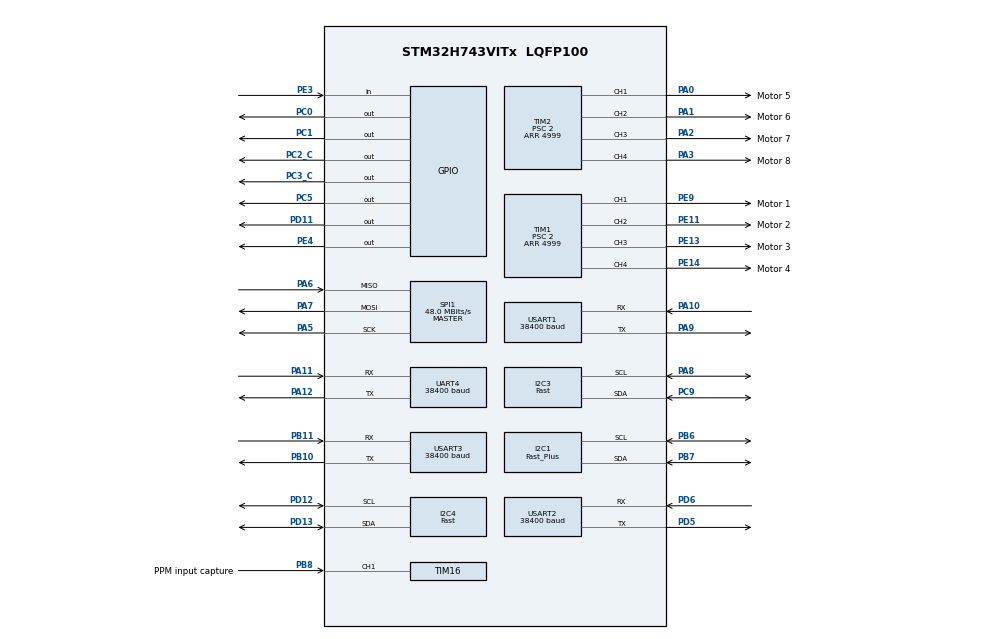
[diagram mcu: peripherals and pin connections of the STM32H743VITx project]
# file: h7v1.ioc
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Bdma.I2C4_RX.0.Direction=DMA_PERIPH_TO_MEMORY
Bdma.I2C4_RX.0.EventEnable=DISABLE
Bdma.I2C4_RX.0.Instance=BDMA_Channel0
Bdma.I2C4_RX.0.MemDataAlignment=DMA_MDATAALIGN_BYTE
Bdma.I2C4_RX.0.MemInc=DMA_MINC_ENABLE
Bdma.I2C4_RX.0.Mode=DMA_NORMAL
Bdma.I2C4_RX.0.PeriphDataAlignment=DMA_PDATAALIGN_BYTE
Bdma.I2C4_RX.0.PeriphInc=DMA_PINC_DISABLE
Bdma.I2C4_RX.0.Polarity=HAL_DMAMUX_REQ_GEN_RISING
Bdma.I2C4_RX.0.Priority=DMA_PRIORITY_LOW
Bdma.I2C4_RX.0.RequestNumber=1
Bdma.I2C4_RX.0.SignalID=NONE
Bdma.I2C4_RX.0.SyncEnable=DISABLE
Bdma.I2C4_RX.0.SyncPolarity=HAL_DMAMUX_SYNC_NO_EVENT
Bdma.I2C4_RX.0.SyncRequestNumber=1
Bdma.I2C4_RX.0.SyncSignalID=NONE
Bdma.I2C4_TX.1.Direction=DMA_MEMORY_TO_PERIPH
Bdma.I2C4_TX.1.EventEnable=DISABLE
Bdma.I2C4_TX.1.Instance=BDMA_Channel1
Bdma.I2C4_TX.1.MemDataAlignment=DMA_MDATAALIGN_BYTE
Bdma.I2C4_TX.1.MemInc=DMA_MINC_ENABLE
Bdma.I2C4_TX.1.Mode=DMA_NORMAL
Bdma.I2C4_TX.1.PeriphDataAlignment=DMA_PDATAALIGN_BYTE
Bdma.I2C4_TX.1.PeriphInc=DMA_PINC_DISABLE
Bdma.I2C4_TX.1.Polarity=HAL_DMAMUX_REQ_GEN_RISING
Bdma.I2C4_TX.1.Priority=DMA_PRIORITY_LOW
Bdma.I2C4_TX.1.RequestNumber=1
Bdma.I2C4_TX.1.SignalID=NONE
Bdma.I2C4_TX.1.SyncEnable=DISABLE
Bdma.I2C4_TX.1.SyncPolarity=HAL_DMAMUX_SYNC_NO_EVENT
Bdma.I2C4_TX.1.SyncRequestNumber=1
Bdma.I2C4_TX.1.SyncSignalID=NONE
Bdma.Request0=I2C4_RX
Bdma.Request1=I2C4_TX
Bdma.RequestsNb=2
CORTEX_M7.CPU_DCache=Disabled
CORTEX_M7.CPU_ICache=Disabled
CORTEX_M7.default_mode_Activation=0
Dma.I2C1_RX.0.Direction=DMA_PERIPH_TO_MEMORY
Dma.I2C1_RX.0.EventEnable=DISABLE
Dma.I2C1_RX.0.FIFOMode=DMA_FIFOMODE_DISABLE
Dma.I2C1_RX.0.Instance=DMA1_Stream0
Dma.I2C1_RX.0.MemDataAlignment=DMA_MDATAALIGN_BYTE
Dma.I2C1_RX.0.MemInc=DMA_MINC_ENABLE
Dma.I2C1_RX.0.Mode=DMA_NORMAL
Dma.I2C1_RX.0.PeriphDataAlignment=DMA_PDATAALIGN_BYTE
Dma.I2C1_RX.0.PeriphInc=DMA_PINC_DISABLE
Dma.I2C1_RX.0.Polarity=HAL_DMAMUX_REQ_GEN_RISING
Dma.I2C1_RX.0.Priority=DMA_PRIORITY_LOW
Dma.I2C1_RX.0.RequestNumber=1
Dma.I2C1_RX.0.SignalID=NONE
Dma.I2C1_RX.0.SyncEnable=DISABLE
Dma.I2C1_RX.0.SyncPolarity=HAL_DMAMUX_SYNC_NO_EVENT
Dma.I2C1_RX.0.SyncRequestNumber=1
Dma.I2C1_RX.0.SyncSignalID=NONE
Dma.I2C1_TX.1.Direction=DMA_MEMORY_TO_PERIPH
Dma.I2C1_TX.1.EventEnable=DISABLE
Dma.I2C1_TX.1.FIFOMode=DMA_FIFOMODE_DISABLE
Dma.I2C1_TX.1.Instance=DMA2_Stream0
Dma.I2C1_TX.1.MemDataAlignment=DMA_MDATAALIGN_BYTE
Dma.I2C1_TX.1.MemInc=DMA_MINC_ENABLE
Dma.I2C1_TX.1.Mode=DMA_NORMAL
Dma.I2C1_TX.1.PeriphDataAlignment=DMA_PDATAALIGN_BYTE
Dma.I2C1_TX.1.PeriphInc=DMA_PINC_DISABLE
Dma.I2C1_TX.1.Polarity=HAL_DMAMUX_REQ_GEN_RISING
Dma.I2C1_TX.1.Priority=DMA_PRIORITY_LOW
Dma.I2C1_TX.1.RequestNumber=1
Dma.I2C1_TX.1.SignalID=NONE
Dma.I2C1_TX.1.SyncEnable=DISABLE
Dma.I2C1_TX.1.SyncPolarity=HAL_DMAMUX_SYNC_NO_EVENT
Dma.I2C1_TX.1.SyncRequestNumber=1
Dma.I2C1_TX.1.SyncSignalID=NONE
Dma.I2C3_RX.7.Direction=DMA_PERIPH_TO_MEMORY
Dma.I2C3_RX.7.EventEnable=DISABLE
Dma.I2C3_RX.7.FIFOMode=DMA_FIFOMODE_DISABLE
Dma.I2C3_RX.7.Instance=DMA2_Stream6
Dma.I2C3_RX.7.MemDataAlignment=DMA_MDATAALIGN_BYTE
Dma.I2C3_RX.7.MemInc=DMA_MINC_ENABLE
Dma.I2C3_RX.7.Mode=DMA_NORMAL
Dma.I2C3_RX.7.PeriphDataAlignment=DMA_PDATAALIGN_BYTE
Dma.I2C3_RX.7.PeriphInc=DMA_PINC_DISABLE
Dma.I2C3_RX.7.Polarity=HAL_DMAMUX_REQ_GEN_RISING
Dma.I2C3_RX.7.Priority=DMA_PRIORITY_LOW
Dma.I2C3_RX.7.RequestNumber=1
Dma.I2C3_RX.7.SignalID=NONE
Dma.I2C3_RX.7.SyncEnable=DISABLE
Dma.I2C3_RX.7.SyncPolarity=HAL_DMAMUX_SYNC_NO_EVENT
Dma.I2C3_RX.7.SyncRequestNumber=1
Dma.I2C3_RX.7.SyncSignalID=NONE
Dma.I2C3_TX.8.Direction=DMA_MEMORY_TO_PERIPH
Dma.I2C3_TX.8.EventEnable=DISABLE
Dma.I2C3_TX.8.FIFOMode=DMA_FIFOMODE_DISABLE
Dma.I2C3_TX.8.Instance=DMA2_Stream7
Dma.I2C3_TX.8.MemDataAlignment=DMA_MDATAALIGN_BYTE
Dma.I2C3_TX.8.MemInc=DMA_MINC_ENABLE
Dma.I2C3_TX.8.Mode=DMA_NORMAL
Dma.I2C3_TX.8.PeriphDataAlignment=DMA_PDATAALIGN_BYTE
Dma.I2C3_TX.8.PeriphInc=DMA_PINC_DISABLE
Dma.I2C3_TX.8.Polarity=HAL_DMAMUX_REQ_GEN_RISING
Dma.I2C3_TX.8.Priority=DMA_PRIORITY_LOW
Dma.I2C3_TX.8.RequestNumber=1
Dma.I2C3_TX.8.SignalID=NONE
Dma.I2C3_TX.8.SyncEnable=DISABLE
Dma.I2C3_TX.8.SyncPolarity=HAL_DMAMUX_SYNC_NO_EVENT
Dma.I2C3_TX.8.SyncRequestNumber=1
Dma.I2C3_TX.8.SyncSignalID=NONE
Dma.Request0=I2C1_RX
Dma.Request1=I2C1_TX
Dma.Request10=TIM2_CH1
Dma.Request11=TIM2_CH2
Dma.Request12=TIM2_CH3
Dma.Request13=TIM2_CH4
Dma.Request14=UART4_RX
Dma.Request15=USART2_RX
Dma.Request2=USART1_RX
Dma.Request3=TIM1_CH1
Dma.Request4=TIM1_CH2
Dma.Request5=TIM1_CH3
Dma.Request6=TIM1_CH4
Dma.Request7=I2C3_RX
Dma.Request8=I2C3_TX
Dma.Request9=USART3_RX
Dma.TIM1_CH1.3.Direction=DMA_MEMORY_TO_PERIPH
Dma.TIM1_CH1.3.EventEnable=DISABLE
Dma.TIM1_CH1.3.FIFOMode=DMA_FIFOMODE_ENABLE
Dma.TIM1_CH1.3.FIFOThreshold=DMA_FIFO_THRESHOLD_1QUARTERFULL
Dma.TIM1_CH1.3.Instance=DMA1_Stream2
Dma.TIM1_CH1.3.MemBurst=DMA_MBURST_SINGLE
Dma.TIM1_CH1.3.MemDataAlignment=DMA_MDATAALIGN_WORD
Dma.TIM1_CH1.3.MemInc=DMA_MINC_ENABLE
Dma.TIM1_CH1.3.Mode=DMA_NORMAL
Dma.TIM1_CH1.3.PeriphBurst=DMA_PBURST_SINGLE
Dma.TIM1_CH1.3.PeriphDataAlignment=DMA_PDATAALIGN_WORD
Dma.TIM1_CH1.3.PeriphInc=DMA_PINC_DISABLE
Dma.TIM1_CH1.3.Polarity=HAL_DMAMUX_REQ_GEN_RISING
Dma.TIM1_CH1.3.Priority=DMA_PRIORITY_HIGH
Dma.TIM1_CH1.3.RequestNumber=1
Dma.TIM1_CH1.3.SignalID=NONE
Dma.TIM1_CH1.3.SyncEnable=DISABLE
Dma.TIM1_CH1.3.SyncPolarity=HAL_DMAMUX_SYNC_NO_EVENT
Dma.TIM1_CH1.3.SyncRequestNumber=1
Dma.TIM1_CH1.3.SyncSignalID=NONE
Dma.TIM1_CH2.4.Direction=DMA_MEMORY_TO_PERIPH
Dma.TIM1_CH2.4.EventEnable=DISABLE
Dma.TIM1_CH2.4.FIFOMode=DMA_FIFOMODE_ENABLE
Dma.TIM1_CH2.4.FIFOThreshold=DMA_FIFO_THRESHOLD_1QUARTERFULL
Dma.TIM1_CH2.4.Instance=DMA1_Stream4
Dma.TIM1_CH2.4.MemBurst=DMA_MBURST_SINGLE
Dma.TIM1_CH2.4.MemDataAlignment=DMA_MDATAALIGN_WORD
Dma.TIM1_CH2.4.MemInc=DMA_MINC_ENABLE
Dma.TIM1_CH2.4.Mode=DMA_NORMAL
Dma.TIM1_CH2.4.PeriphBurst=DMA_PBURST_SINGLE
Dma.TIM1_CH2.4.PeriphDataAlignment=DMA_PDATAALIGN_WORD
Dma.TIM1_CH2.4.PeriphInc=DMA_PINC_DISABLE
Dma.TIM1_CH2.4.Polarity=HAL_DMAMUX_REQ_GEN_RISING
Dma.TIM1_CH2.4.Priority=DMA_PRIORITY_HIGH
Dma.TIM1_CH2.4.RequestNumber=1
Dma.TIM1_CH2.4.SignalID=NONE
Dma.TIM1_CH2.4.SyncEnable=DISABLE
Dma.TIM1_CH2.4.SyncPolarity=HAL_DMAMUX_SYNC_NO_EVENT
Dma.TIM1_CH2.4.SyncRequestNumber=1
Dma.TIM1_CH2.4.SyncSignalID=NONE
Dma.TIM1_CH3.5.Direction=DMA_MEMORY_TO_PERIPH
Dma.TIM1_CH3.5.EventEnable=DISABLE
Dma.TIM1_CH3.5.FIFOMode=DMA_FIFOMODE_ENABLE
Dma.TIM1_CH3.5.FIFOThreshold=DMA_FIFO_THRESHOLD_1QUARTERFULL
Dma.TIM1_CH3.5.Instance=DMA1_Stream7
Dma.TIM1_CH3.5.MemBurst=DMA_MBURST_SINGLE
Dma.TIM1_CH3.5.MemDataAlignment=DMA_MDATAALIGN_WORD
Dma.TIM1_CH3.5.MemInc=DMA_MINC_ENABLE
Dma.TIM1_CH3.5.Mode=DMA_NORMAL
Dma.TIM1_CH3.5.PeriphBurst=DMA_PBURST_SINGLE
Dma.TIM1_CH3.5.PeriphDataAlignment=DMA_PDATAALIGN_WORD
Dma.TIM1_CH3.5.PeriphInc=DMA_PINC_DISABLE
Dma.TIM1_CH3.5.Polarity=HAL_DMAMUX_REQ_GEN_RISING
Dma.TIM1_CH3.5.Priority=DMA_PRIORITY_HIGH
Dma.TIM1_CH3.5.RequestNumber=1
Dma.TIM1_CH3.5.SignalID=NONE
Dma.TIM1_CH3.5.SyncEnable=DISABLE
Dma.TIM1_CH3.5.SyncPolarity=HAL_DMAMUX_SYNC_NO_EVENT
Dma.TIM1_CH3.5.SyncRequestNumber=1
Dma.TIM1_CH3.5.SyncSignalID=NONE
Dma.TIM1_CH4.6.Direction=DMA_MEMORY_TO_PERIPH
Dma.TIM1_CH4.6.EventEnable=DISABLE
Dma.TIM1_CH4.6.FIFOMode=DMA_FIFOMODE_ENABLE
Dma.TIM1_CH4.6.FIFOThreshold=DMA_FIFO_THRESHOLD_1QUARTERFULL
Dma.TIM1_CH4.6.Instance=DMA2_Stream1
Dma.TIM1_CH4.6.MemBurst=DMA_MBURST_SINGLE
Dma.TIM1_CH4.6.MemDataAlignment=DMA_MDATAALIGN_WORD
Dma.TIM1_CH4.6.MemInc=DMA_MINC_ENABLE
Dma.TIM1_CH4.6.Mode=DMA_NORMAL
Dma.TIM1_CH4.6.PeriphBurst=DMA_PBURST_SINGLE
Dma.TIM1_CH4.6.PeriphDataAlignment=DMA_PDATAALIGN_WORD
Dma.TIM1_CH4.6.PeriphInc=DMA_PINC_DISABLE
Dma.TIM1_CH4.6.Polarity=HAL_DMAMUX_REQ_GEN_RISING
Dma.TIM1_CH4.6.Priority=DMA_PRIORITY_HIGH
Dma.TIM1_CH4.6.RequestNumber=1
Dma.TIM1_CH4.6.SignalID=NONE
Dma.TIM1_CH4.6.SyncEnable=DISABLE
Dma.TIM1_CH4.6.SyncPolarity=HAL_DMAMUX_SYNC_NO_EVENT
Dma.TIM1_CH4.6.SyncRequestNumber=1
Dma.TIM1_CH4.6.SyncSignalID=NONE
Dma.TIM2_CH1.10.Direction=DMA_MEMORY_TO_PERIPH
Dma.TIM2_CH1.10.EventEnable=DISABLE
Dma.TIM2_CH1.10.FIFOMode=DMA_FIFOMODE_ENABLE
Dma.TIM2_CH1.10.FIFOThreshold=DMA_FIFO_THRESHOLD_FULL
Dma.TIM2_CH1.10.Instance=DMA1_Stream3
Dma.TIM2_CH1.10.MemBurst=DMA_MBURST_SINGLE
Dma.TIM2_CH1.10.MemDataAlignment=DMA_MDATAALIGN_WORD
Dma.TIM2_CH1.10.MemInc=DMA_MINC_ENABLE
Dma.TIM2_CH1.10.Mode=DMA_NORMAL
Dma.TIM2_CH1.10.PeriphBurst=DMA_PBURST_SINGLE
Dma.TIM2_CH1.10.PeriphDataAlignment=DMA_PDATAALIGN_WORD
Dma.TIM2_CH1.10.PeriphInc=DMA_PINC_DISABLE
Dma.TIM2_CH1.10.Polarity=HAL_DMAMUX_REQ_GEN_RISING
Dma.TIM2_CH1.10.Priority=DMA_PRIORITY_HIGH
Dma.TIM2_CH1.10.RequestNumber=1
Dma.TIM2_CH1.10.SignalID=NONE
Dma.TIM2_CH1.10.SyncEnable=DISABLE
Dma.TIM2_CH1.10.SyncPolarity=HAL_DMAMUX_SYNC_NO_EVENT
Dma.TIM2_CH1.10.SyncRequestNumber=1
Dma.TIM2_CH1.10.SyncSignalID=NONE
Dma.TIM2_CH2.11.Direction=DMA_MEMORY_TO_PERIPH
Dma.TIM2_CH2.11.EventEnable=DISABLE
Dma.TIM2_CH2.11.FIFOMode=DMA_FIFOMODE_ENABLE
Dma.TIM2_CH2.11.FIFOThreshold=DMA_FIFO_THRESHOLD_FULL
Dma.TIM2_CH2.11.Instance=DMA1_Stream5
Dma.TIM2_CH2.11.MemBurst=DMA_MBURST_SINGLE
Dma.TIM2_CH2.11.MemDataAlignment=DMA_MDATAALIGN_WORD
Dma.TIM2_CH2.11.MemInc=DMA_MINC_ENABLE
Dma.TIM2_CH2.11.Mode=DMA_NORMAL
Dma.TIM2_CH2.11.PeriphBurst=DMA_PBURST_SINGLE
Dma.TIM2_CH2.11.PeriphDataAlignment=DMA_PDATAALIGN_WORD
Dma.TIM2_CH2.11.PeriphInc=DMA_PINC_DISABLE
Dma.TIM2_CH2.11.Polarity=HAL_DMAMUX_REQ_GEN_RISING
Dma.TIM2_CH2.11.Priority=DMA_PRIORITY_HIGH
Dma.TIM2_CH2.11.RequestNumber=1
Dma.TIM2_CH2.11.SignalID=NONE
Dma.TIM2_CH2.11.SyncEnable=DISABLE
Dma.TIM2_CH2.11.SyncPolarity=HAL_DMAMUX_SYNC_NO_EVENT
Dma.TIM2_CH2.11.SyncRequestNumber=1
Dma.TIM2_CH2.11.SyncSignalID=NONE
Dma.TIM2_CH3.12.Direction=DMA_MEMORY_TO_PERIPH
Dma.TIM2_CH3.12.EventEnable=DISABLE
Dma.TIM2_CH3.12.FIFOMode=DMA_FIFOMODE_ENABLE
Dma.TIM2_CH3.12.FIFOThreshold=DMA_FIFO_THRESHOLD_FULL
Dma.TIM2_CH3.12.Instance=DMA2_Stream2
Dma.TIM2_CH3.12.MemBurst=DMA_MBURST_SINGLE
Dma.TIM2_CH3.12.MemDataAlignment=DMA_MDATAALIGN_WORD
Dma.TIM2_CH3.12.MemInc=DMA_MINC_ENABLE
Dma.TIM2_CH3.12.Mode=DMA_NORMAL
Dma.TIM2_CH3.12.PeriphBurst=DMA_PBURST_SINGLE
Dma.TIM2_CH3.12.PeriphDataAlignment=DMA_PDATAALIGN_WORD
Dma.TIM2_CH3.12.PeriphInc=DMA_PINC_DISABLE
Dma.TIM2_CH3.12.Polarity=HAL_DMAMUX_REQ_GEN_RISING
Dma.TIM2_CH3.12.Priority=DMA_PRIORITY_HIGH
Dma.TIM2_CH3.12.RequestNumber=1
Dma.TIM2_CH3.12.SignalID=NONE
Dma.TIM2_CH3.12.SyncEnable=DISABLE
Dma.TIM2_CH3.12.SyncPolarity=HAL_DMAMUX_SYNC_NO_EVENT
Dma.TIM2_CH3.12.SyncRequestNumber=1
Dma.TIM2_CH3.12.SyncSignalID=NONE
Dma.TIM2_CH4.13.Direction=DMA_MEMORY_TO_PERIPH
Dma.TIM2_CH4.13.EventEnable=DISABLE
Dma.TIM2_CH4.13.FIFOMode=DMA_FIFOMODE_ENABLE
Dma.TIM2_CH4.13.FIFOThreshold=DMA_FIFO_THRESHOLD_1QUARTERFULL
Dma.TIM2_CH4.13.Instance=DMA2_Stream3
Dma.TIM2_CH4.13.MemBurst=DMA_MBURST_SINGLE
Dma.TIM2_CH4.13.MemDataAlignment=DMA_MDATAALIGN_WORD
Dma.TIM2_CH4.13.MemInc=DMA_MINC_ENABLE
Dma.TIM2_CH4.13.Mode=DMA_NORMAL
Dma.TIM2_CH4.13.PeriphBurst=DMA_PBURST_SINGLE
Dma.TIM2_CH4.13.PeriphDataAlignment=DMA_PDATAALIGN_WORD
Dma.TIM2_CH4.13.PeriphInc=DMA_PINC_DISABLE
Dma.TIM2_CH4.13.Polarity=HAL_DMAMUX_REQ_GEN_RISING
Dma.TIM2_CH4.13.Priority=DMA_PRIORITY_HIGH
Dma.TIM2_CH4.13.RequestNumber=1
Dma.TIM2_CH4.13.SignalID=NONE
Dma.TIM2_CH4.13.SyncEnable=DISABLE
Dma.TIM2_CH4.13.SyncPolarity=HAL_DMAMUX_SYNC_NO_EVENT
Dma.TIM2_CH4.13.SyncRequestNumber=1
Dma.TIM2_CH4.13.SyncSignalID=NONE
Dma.UART4_RX.14.Direction=DMA_PERIPH_TO_MEMORY
Dma.UART4_RX.14.EventEnable=DISABLE
Dma.UART4_RX.14.FIFOMode=DMA_FIFOMODE_DISABLE
Dma.UART4_RX.14.Instance=DMA2_Stream4
Dma.UART4_RX.14.MemDataAlignment=DMA_MDATAALIGN_BYTE
Dma.UART4_RX.14.MemInc=DMA_MINC_ENABLE
Dma.UART4_RX.14.Mode=DMA_CIRCULAR
Dma.UART4_RX.14.PeriphDataAlignment=DMA_PDATAALIGN_BYTE
Dma.UART4_RX.14.PeriphInc=DMA_PINC_DISABLE
Dma.UART4_RX.14.Polarity=HAL_DMAMUX_REQ_GEN_RISING
Dma.UART4_RX.14.Priority=DMA_PRIORITY_LOW
Dma.UART4_RX.14.RequestNumber=1
Dma.UART4_RX.14.SignalID=NONE
Dma.UART4_RX.14.SyncEnable=DISABLE
Dma.UART4_RX.14.SyncPolarity=HAL_DMAMUX_SYNC_NO_EVENT
Dma.UART4_RX.14.SyncRequestNumber=1
Dma.UART4_RX.14.SyncSignalID=NONE
Dma.USART1_RX.2.Direction=DMA_PERIPH_TO_MEMORY
Dma.USART1_RX.2.EventEnable=DISABLE
Dma.USART1_RX.2.FIFOMode=DMA_FIFOMODE_DISABLE
Dma.USART1_RX.2.Instance=DMA1_Stream6
Dma.USART1_RX.2.MemDataAlignment=DMA_MDATAALIGN_BYTE
Dma.USART1_RX.2.MemInc=DMA_MINC_ENABLE
Dma.USART1_RX.2.Mode=DMA_CIRCULAR
Dma.USART1_RX.2.PeriphDataAlignment=DMA_PDATAALIGN_BYTE
Dma.USART1_RX.2.PeriphInc=DMA_PINC_DISABLE
Dma.USART1_RX.2.Polarity=HAL_DMAMUX_REQ_GEN_RISING
Dma.USART1_RX.2.Priority=DMA_PRIORITY_LOW
Dma.USART1_RX.2.RequestNumber=1
Dma.USART1_RX.2.SignalID=NONE
Dma.USART1_RX.2.SyncEnable=DISABLE
Dma.USART1_RX.2.SyncPolarity=HAL_DMAMUX_SYNC_NO_EVENT
Dma.USART1_RX.2.SyncRequestNumber=1
Dma.USART1_RX.2.SyncSignalID=NONE
Dma.USART2_RX.15.Direction=DMA_PERIPH_TO_MEMORY
Dma.USART2_RX.15.EventEnable=DISABLE
Dma.USART2_RX.15.FIFOMode=DMA_FIFOMODE_DISABLE
Dma.USART2_RX.15.Instance=DMA2_Stream5
Dma.USART2_RX.15.MemDataAlignment=DMA_MDATAALIGN_BYTE
Dma.USART2_RX.15.MemInc=DMA_MINC_ENABLE
Dma.USART2_RX.15.Mode=DMA_CIRCULAR
Dma.USART2_RX.15.PeriphDataAlignment=DMA_PDATAALIGN_BYTE
Dma.USART2_RX.15.PeriphInc=DMA_PINC_DISABLE
Dma.USART2_RX.15.Polarity=HAL_DMAMUX_REQ_GEN_RISING
Dma.USART2_RX.15.Priority=DMA_PRIORITY_LOW
Dma.USART2_RX.15.RequestNumber=1
Dma.USART2_RX.15.SignalID=NONE
Dma.USART2_RX.15.SyncEnable=DISABLE
Dma.USART2_RX.15.SyncPolarity=HAL_DMAMUX_SYNC_NO_EVENT
Dma.USART2_RX.15.SyncRequestNumber=1
Dma.USART2_RX.15.SyncSignalID=NONE
Dma.USART3_RX.9.Direction=DMA_PERIPH_TO_MEMORY
Dma.USART3_RX.9.EventEnable=DISABLE
Dma.USART3_RX.9.FIFOMode=DMA_FIFOMODE_DISABLE
Dma.USART3_RX.9.Instance=DMA1_Stream1
Dma.USART3_RX.9.MemDataAlignment=DMA_MDATAALIGN_BYTE
Dma.USART3_RX.9.MemInc=DMA_MINC_ENABLE
Dma.USART3_RX.9.Mode=DMA_CIRCULAR
Dma.USART3_RX.9.PeriphDataAlignment=DMA_PDATAALIGN_BYTE
Dma.USART3_RX.9.PeriphInc=DMA_PINC_DISABLE
Dma.USART3_RX.9.Polarity=HAL_DMAMUX_REQ_GEN_RISING
Dma.USART3_RX.9.Priority=DMA_PRIORITY_LOW
Dma.USART3_RX.9.RequestNumber=1
Dma.USART3_RX.9.SignalID=NONE
Dma.USART3_RX.9.SyncEnable=DISABLE
Dma.USART3_RX.9.SyncPolarity=HAL_DMAMUX_SYNC_NO_EVENT
Dma.USART3_RX.9.SyncRequestNumber=1
Dma.USART3_RX.9.SyncSignalID=NONE
I2C1.I2C_Speed_Mode=I2C_Fast_Plus
I2C1.Timing=0x0050174F
I2C3.I2C_Speed_Mode=I2C_Fast
I2C3.OwnAddress=0x68
I2C3.Timing=0x00B03FDB
I2C4.I2C_Speed_Mode=I2C_Fast
I2C4.Timing=0x00B03FDB
Mcu.Family=STM32H7
Mcu.Name=STM32H743VITx
Mcu.Package=LQFP100
NVIC.BDMA_Channel0_IRQn=true\:0\:0\:false\:false\:true\:false\:true\:true
NVIC.BDMA_Channel1_IRQn=true\:0\:0\:false\:false\:true\:false\:true\:true
NVIC.DMA1_Stream0_IRQn=true\:0\:0\:false\:false\:true\:false\:true\:true
NVIC.DMA1_Stream1_IRQn=true\:0\:0\:false\:false\:true\:false\:true\:true
NVIC.DMA1_Stream2_IRQn=true\:0\:0\:false\:false\:true\:false\:true\:true
NVIC.DMA1_Stream3_IRQn=true\:0\:0\:false\:false\:true\:false\:true\:true
NVIC.DMA1_Stream4_IRQn=true\:0\:0\:false\:false\:true\:false\:true\:true
NVIC.DMA1_Stream5_IRQn=true\:0\:0\:false\:false\:true\:false\:true\:true
NVIC.DMA1_Stream6_IRQn=true\:0\:0\:false\:false\:true\:false\:true\:true
NVIC.DMA1_Stream7_IRQn=true\:0\:0\:false\:false\:true\:false\:true\:true
NVIC.DMA2_Stream0_IRQn=true\:0\:0\:false\:false\:true\:false\:true\:true
NVIC.DMA2_Stream1_IRQn=true\:0\:0\:false\:false\:true\:false\:true\:true
NVIC.DMA2_Stream2_IRQn=true\:0\:0\:false\:false\:true\:false\:true\:true
NVIC.DMA2_Stream3_IRQn=true\:0\:0\:false\:false\:true\:false\:true\:true
NVIC.DMA2_Stream4_IRQn=true\:0\:0\:false\:false\:true\:false\:true\:true
NVIC.DMA2_Stream5_IRQn=true\:0\:0\:false\:false\:true\:false\:true\:true
NVIC.DMA2_Stream6_IRQn=true\:0\:0\:false\:false\:true\:false\:true\:true
NVIC.DMA2_Stream7_IRQn=true\:0\:0\:false\:false\:true\:false\:true\:true
NVIC.I2C1_ER_IRQn=true\:0\:0\:false\:false\:true\:true\:true\:true
NVIC.I2C1_EV_IRQn=true\:0\:0\:false\:false\:true\:true\:true\:true
NVIC.I2C3_ER_IRQn=true\:0\:0\:false\:false\:true\:true\:true\:true
NVIC.I2C3_EV_IRQn=true\:0\:0\:false\:false\:true\:true\:true\:true
NVIC.PriorityGroup=NVIC_PRIORITYGROUP_4
NVIC.TIM16_IRQn=true\:0\:0\:false\:false\:true\:true\:true\:true
NVIC.TIM6_DAC_IRQn=true\:0\:0\:false\:false\:true\:true\:true\:true
NVIC.TIM7_IRQn=true\:0\:0\:false\:false\:true\:true\:true\:true
NVIC.TIM8_TRG_COM_TIM14_IRQn=true\:0\:0\:false\:false\:true\:true\:true\:true
NVIC.TIM8_UP_TIM13_IRQn=true\:0\:0\:false\:false\:true\:true\:true\:true
NVIC.UART4_IRQn=true\:0\:0\:false\:false\:true\:true\:true\:true
NVIC.USART1_IRQn=true\:0\:0\:false\:false\:true\:true\:true\:true
NVIC.USART2_IRQn=true\:0\:0\:false\:false\:true\:true\:true\:true
NVIC.USART3_IRQn=true\:0\:0\:false\:false\:true\:true\:true\:true
PA0.GPIO_Label=Motor 5
PA0.Signal=S_TIM2_CH1_ETR
PA1.GPIO_Label=Motor 6
PA1.Signal=S_TIM2_CH2
PA10.Mode=Asynchronous
PA10.Signal=USART1_RX
PA11.GPIO_PuPd=GPIO_PULLUP
PA11.Mode=Asynchronous
PA11.Signal=UART4_RX
PA12.GPIO_PuPd=GPIO_PULLUP
PA12.Mode=Asynchronous
PA12.Signal=UART4_TX
PA13\ (JTMS/SWDIO).Mode=Serial_Wire
PA13\ (JTMS/SWDIO).Signal=DEBUG_JTMS-SWDIO
PA14\ (JTCK/SWCLK).Mode=Serial_Wire
PA14\ (JTCK/SWCLK).Signal=DEBUG_JTCK-SWCLK
PA2.GPIO_Label=Motor 7
PA2.Signal=S_TIM2_CH3
PA3.GPIO_Label=Motor 8
PA3.Signal=S_TIM2_CH4
PA5.Mode=Full_Duplex_Master
PA5.Signal=SPI1_SCK
PA6.Mode=Full_Duplex_Master
PA6.Signal=SPI1_MISO
PA7.Mode=Full_Duplex_Master
PA7.Signal=SPI1_MOSI
PA8.Mode=I2C
PA8.Signal=I2C3_SCL
PA9.Mode=Asynchronous
PA9.Signal=USART1_TX
PB10.GPIO_PuPd=GPIO_PULLUP
PB10.Mode=Asynchronous
PB10.Signal=USART3_TX
PB11.GPIO_PuPd=GPIO_PULLUP
PB11.Mode=Asynchronous
PB11.Signal=USART3_RX
PB6.Mode=I2C
PB6.Signal=I2C1_SCL
PB7.Mode=I2C
PB7.Signal=I2C1_SDA
PB8.GPIO_Label=PPM input capture
PB8.Signal=S_TIM16_CH1
PC0.Signal=GPIO_Output
PC1.Signal=GPIO_Output
PC2_C.Signal=GPIO_Output
PC3_C.Signal=GPIO_Output
PC5.Signal=GPIO_Output
PC9.Mode=I2C
PC9.Signal=I2C3_SDA
PD11.Signal=GPIO_Output
PD12.Mode=I2C
PD12.Signal=I2C4_SCL
PD13.Mode=I2C
PD13.Signal=I2C4_SDA
PD5.GPIO_PuPd=GPIO_PULLUP
PD5.Mode=Asynchronous
PD5.PinAttribute=Free
PD5.Signal=USART2_TX
PD6.GPIO_PuPd=GPIO_PULLUP
PD6.Mode=Asynchronous
PD6.PinAttribute=Free
PD6.Signal=USART2_RX
PE11.GPIO_Label=Motor 2
PE11.Signal=S_TIM1_CH2
PE13.GPIO_Label=Motor 3
PE13.Signal=S_TIM1_CH3
PE14.GPIO_Label=Motor 4
PE14.Signal=S_TIM1_CH4
PE3.Signal=GPIO_Input
PE4.Signal=GPIO_Output
PE5.Signal=S_TIM15_CH1
PE6.Signal=S_TIM15_CH2
PE9.GPIO_Label=Motor 1
PE9.Signal=S_TIM1_CH1
PH0-OSC_IN\ (PH0).Mode=HSE-External-Oscillator
PH0-OSC_IN\ (PH0).Signal=RCC_OSC_IN
PH1-OSC_OUT\ (PH1).Mode=HSE-External-Oscillator
PH1-OSC_OUT\ (PH1).Signal=RCC_OSC_OUT
ProjectManager.HeapSize=0x200
ProjectManager.StackSize=0x400
ProjectManager.TargetToolchain=STM32CubeIDE
RCC.ADCFreq_Value=480000000
RCC.APB1Freq_Value=120000000
RCC.APB2Freq_Value=120000000
RCC.APB3Freq_Value=120000000
RCC.APB4Freq_Value=120000000
RCC.CortexFreq_Value=480000000
RCC.D1PPRE=RCC_APB3_DIV2
RCC.D2PPRE1=RCC_APB1_DIV2
RCC.D2PPRE2=RCC_APB2_DIV2
RCC.D3PPRE=RCC_APB4_DIV2
RCC.DIVM1=12
RCC.DIVM2=12
RCC.DIVM3=12
RCC.DIVN1=480
RCC.DIVN2=480
RCC.DIVN3=480
RCC.DIVQ1=5
RCC.DIVQ2=8
RCC.DIVQ3=8
RCC.DIVR3=8
RCC.HCLKFreq_Value=240000000
RCC.HPRE=RCC_HCLK_DIV2
RCC.HSE_VALUE=24000000
RCC.HSIDiv=RCC_PLLSAIDIVR_8
RCC.I2C123CLockSelection=RCC_I2C123CLKSOURCE_PLL3
RCC.I2C4CLockSelection=RCC_I2C4CLKSOURCE_PLL3
RCC.PLL1_VCI_Range-AdvancedSettings=RCC_PLL1VCIRANGE_0
RCC.PLL2FRACN=0
RCC.PLL2_VCI_Range-AdvancedSettings=RCC_PLL2VCIRANGE_3
RCC.PLL3FRACN=0
RCC.PLLFRACN=0
RCC.PLLSourceVirtual=RCC_PLLSOURCE_HSE
RCC.SYSCLKFreq_VALUE=480000000
RCC.SYSCLKSource=RCC_SYSCLKSOURCE_PLLCLK
RCC.USART16CLockSelection=RCC_USART16CLKSOURCE_PLL3
RCC.USART234578CLockSelection=RCC_USART234578CLKSOURCE_PLL3
RCC.USBCLockSelection=RCC_USBCLKSOURCE_HSI48
RCC.USBFreq_Value=48000000
SH.S_TIM15_CH1.0=TIM15_CH1
SH.S_TIM15_CH2.0=TIM15_CH2
SH.S_TIM16_CH1.0=TIM16_CH1,Input_Capture1_from_TI1
SH.S_TIM1_CH1.0=TIM1_CH1,PWM Generation1 CH1
SH.S_TIM1_CH2.0=TIM1_CH2,PWM Generation2 CH2
SH.S_TIM1_CH3.0=TIM1_CH3,PWM Generation3 CH3
SH.S_TIM1_CH4.0=TIM1_CH4,PWM Generation4 CH4
SH.S_TIM2_CH1_ETR.0=TIM2_CH1,PWM Generation1 CH1
SH.S_TIM2_CH2.0=TIM2_CH2,PWM Generation2 CH2
SH.S_TIM2_CH3.0=TIM2_CH3,PWM Generation3 CH3
SH.S_TIM2_CH4.0=TIM2_CH4,PWM Generation4 CH4
SPI1.BaudRatePrescaler=SPI_BAUDRATEPRESCALER_4
SPI1.CalculateBaudRate=48.0 MBits/s
SPI1.Direction=SPI_DIRECTION_2LINES
SPI1.Mode=SPI_MODE_MASTER
SPI1.VirtualType=VM_MASTER
TIM1.Channel-PWM\ Generation1\ CH1=TIM_CHANNEL_1
TIM1.Channel-PWM\ Generation2\ CH2=TIM_CHANNEL_2
TIM1.Channel-PWM\ Generation3\ CH3=TIM_CHANNEL_3
TIM1.Channel-PWM\ Generation4\ CH4=TIM_CHANNEL_4
TIM1.Period=4999
TIM1.Prescaler=2
TIM13.Period=999
TIM13.Prescaler=239
TIM14.Period=124
TIM14.Prescaler=239
TIM16.Channel=TIM_CHANNEL_1
TIM16.Prescaler=239
TIM2.Channel-PWM\ Generation1\ CH1=TIM_CHANNEL_1
TIM2.Channel-PWM\ Generation2\ CH2=TIM_CHANNEL_2
TIM2.Channel-PWM\ Generation3\ CH3=TIM_CHANNEL_3
TIM2.Channel-PWM\ Generation4\ CH4=TIM_CHANNEL_4
TIM2.Period=4999
TIM2.Prescaler=2
TIM6.Period=249
TIM6.Prescaler=239
TIM7.Period=499
TIM7.Prescaler=239
UART4.BaudRate=38400
USART1.BaudRate=38400
USART1.VirtualMode-Asynchronous=VM_ASYNC
USART2.BaudRate=38400
USART2.VirtualMode-Asynchronous=VM_ASYNC
USART3.BaudRate=38400
USART3.VirtualMode-Asynchronous=VM_ASYNC
VP_MEMORYMAP_VS_MEMORYMAP.Mode=CurAppReg
VP_TIM13_VS_ClockSourceINT.Mode=Enable_Timer
VP_TIM14_VS_ClockSourceINT.Mode=Enable_Timer
VP_TIM16_VS_ClockSourceINT.Mode=Enable_Timer
VP_TIM1_VS_ClockSourceINT.Mode=Internal
VP_TIM2_VS_ClockSourceINT.Mode=Internal
VP_TIM6_VS_ClockSourceINT.Mode=Enable_Timer
VP_TIM7_VS_ClockSourceINT.Mode=Enable_Timer
board=custom

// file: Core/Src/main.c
/* USER CODE BEGIN Header */
/**
  ******************************************************************************
  * @file           : main.c
  * @brief          : Main program body
  ******************************************************************************
  * @attention
  *
  * Copyright (c) 2025 STMicroelectronics.
  * All rights reserved.
  *
  * This software is licensed under terms that can be found in the LICENSE file
  * in the root directory of this software component.
  * If no LICENSE file comes with this software, it is provided AS-IS.
  *
  ******************************************************************************
  */
/* USER CODE END Header */
#include "main.h"

/* USER CODE BEGIN Includes */
#include <platform.h>
#include <pubsub.h>
#include "platform_storage.h"
#include "platform_hw.h"

/* USER CODE END Includes */

I2C_HandleTypeDef hi2c1;
I2C_HandleTypeDef hi2c3;
I2C_HandleTypeDef hi2c4;
DMA_HandleTypeDef hdma_i2c1_rx;
DMA_HandleTypeDef hdma_i2c1_tx;
DMA_HandleTypeDef hdma_i2c3_rx;
DMA_HandleTypeDef hdma_i2c3_tx;
DMA_HandleTypeDef hdma_i2c4_rx;
DMA_HandleTypeDef hdma_i2c4_tx;

SPI_HandleTypeDef hspi1;

TIM_HandleTypeDef htim1;
TIM_HandleTypeDef htim2;
TIM_HandleTypeDef htim6;
TIM_HandleTypeDef htim7;
TIM_HandleTypeDef htim13;
TIM_HandleTypeDef htim14;
TIM_HandleTypeDef htim16;
DMA_HandleTypeDef hdma_tim1_ch1;
DMA_HandleTypeDef hdma_tim1_ch2;
DMA_HandleTypeDef hdma_tim1_ch3;
DMA_HandleTypeDef hdma_tim1_ch4;
DMA_HandleTypeDef hdma_tim2_ch1;
DMA_HandleTypeDef hdma_tim2_ch2;
DMA_HandleTypeDef hdma_tim2_ch3;
DMA_HandleTypeDef hdma_tim2_ch4;

UART_HandleTypeDef huart4;
UART_HandleTypeDef huart1;
UART_HandleTypeDef huart2;
UART_HandleTypeDef huart3;
DMA_HandleTypeDef hdma_uart4_rx;
DMA_HandleTypeDef hdma_usart1_rx;
DMA_HandleTypeDef hdma_usart2_rx;
DMA_HandleTypeDef hdma_usart3_rx;

void SystemClock_Config(void);
void PeriphCommonClock_Config(void);
static void MX_GPIO_Init(void);
static void MX_DMA_Init(void);
static void MX_BDMA_Init(void);
static void MX_I2C1_Init(void);
static void MX_I2C3_Init(void);
static void MX_I2C4_Init(void);
static void MX_TIM1_Init(void);
static void MX_TIM2_Init(void);
static void MX_TIM6_Init(void);
static void MX_TIM7_Init(void);
static void MX_TIM13_Init(void);
static void MX_TIM14_Init(void);
static void MX_TIM16_Init(void);
static void MX_USART1_UART_Init(void);
static void MX_USART3_UART_Init(void);
static void MX_UART4_Init(void);
static void MX_USART2_UART_Init(void);
static void MX_SPI1_Init(void);

/* USER CODE BEGIN 0 */

/* Platform drivers are in h7v1/platform/ — see platform_uart.c, platform_i2c.c, etc. */

/* USER CODE END 0 */

int main(void)
{

  /* MCU Configuration--------------------------------------------------------*/

  /* Reset of all peripherals, Initializes the Flash interface and the Systick. */
  HAL_Init();

  /* Configure the system clock */
  SystemClock_Config();

  /* Configure the peripherals common clocks */
  PeriphCommonClock_Config();

  /* Initialize all configured peripherals */
  MX_GPIO_Init();
  MX_DMA_Init();
  MX_BDMA_Init();
  MX_I2C1_Init();
  MX_I2C3_Init();
  MX_I2C4_Init();
  MX_TIM1_Init();
  MX_TIM2_Init();
  MX_TIM6_Init();
  MX_TIM7_Init();
  MX_TIM13_Init();
  MX_TIM14_Init();
  MX_TIM16_Init();
  MX_USART1_UART_Init();
  MX_USART3_UART_Init();
  MX_UART4_Init();
  MX_USART2_UART_Init();
  MX_SPI1_Init();
  /* USER CODE BEGIN 2 */

  HAL_Delay(100);

  // Setup platform modules
  platform_setup();

  // Start UART DMA ring buffers (defined in platform/platform_uart.c)
  platform_hw_uart_start();

  // PPM input capture
  HAL_TIM_IC_Start_IT(&htim16, TIM_CHANNEL_1);

  // Start timers
  HAL_TIM_Base_Start_IT(&htim6);
  HAL_TIM_Base_Start_IT(&htim7);
  HAL_TIM_Base_Start_IT(&htim13);
  HAL_TIM_Base_Start_IT(&htim14);

  /* USER CODE END 2 */

  /* Infinite loop */
  /* USER CODE BEGIN WHILE */
  while (1)
  {
	  publish(LOOP, NULL, 0);
    /* USER CODE END WHILE */

  }
}

void SystemClock_Config(void)
{
  RCC_OscInitTypeDef RCC_OscInitStruct = {0};
  RCC_ClkInitTypeDef RCC_ClkInitStruct = {0};

  /** Supply configuration update enable
  */
  HAL_PWREx_ConfigSupply(PWR_LDO_SUPPLY);

  /** Configure the main internal regulator output voltage
  */
  __HAL_PWR_VOLTAGESCALING_CONFIG(PWR_REGULATOR_VOLTAGE_SCALE0);

  while(!__HAL_PWR_GET_FLAG(PWR_FLAG_VOSRDY)) {}

  /** Initializes the RCC Oscillators according to the specified parameters
  * in the RCC_OscInitTypeDef structure.
  */
  RCC_OscInitStruct.OscillatorType = RCC_OSCILLATORTYPE_HSE;
  RCC_OscInitStruct.HSEState = RCC_HSE_ON;
  RCC_OscInitStruct.PLL.PLLState = RCC_PLL_ON;
  RCC_OscInitStruct.PLL.PLLSource = RCC_PLLSOURCE_HSE;
  RCC_OscInitStruct.PLL.PLLM = 12;
  RCC_OscInitStruct.PLL.PLLN = 480;
  RCC_OscInitStruct.PLL.PLLP = 2;
  RCC_OscInitStruct.PLL.PLLQ = 5;
  RCC_OscInitStruct.PLL.PLLR = 2;
  RCC_OscInitStruct.PLL.PLLRGE = RCC_PLL1VCIRANGE_1;
  RCC_OscInitStruct.PLL.PLLVCOSEL = RCC_PLL1VCOWIDE;
  RCC_OscInitStruct.PLL.PLLFRACN = 0;
  if (HAL_RCC_OscConfig(&RCC_OscInitStruct) != HAL_OK)
  {
    Error_Handler();
  }

  /** Initializes the CPU, AHB and APB buses clocks
  */
  RCC_ClkInitStruct.ClockType = RCC_CLOCKTYPE_HCLK|RCC_CLOCKTYPE_SYSCLK
                              |RCC_CLOCKTYPE_PCLK1|RCC_CLOCKTYPE_PCLK2
                              |RCC_CLOCKTYPE_D3PCLK1|RCC_CLOCKTYPE_D1PCLK1;
  RCC_ClkInitStruct.SYSCLKSource = RCC_SYSCLKSOURCE_PLLCLK;
  RCC_ClkInitStruct.SYSCLKDivider = RCC_SYSCLK_DIV1;
  RCC_ClkInitStruct.AHBCLKDivider = RCC_HCLK_DIV2;
  RCC_ClkInitStruct.APB3CLKDivider = RCC_APB3_DIV2;
  RCC_ClkInitStruct.APB1CLKDivider = RCC_APB1_DIV2;
  RCC_ClkInitStruct.APB2CLKDivider = RCC_APB2_DIV2;
  RCC_ClkInitStruct.APB4CLKDivider = RCC_APB4_DIV2;

  if (HAL_RCC_ClockConfig(&RCC_ClkInitStruct, FLASH_LATENCY_4) != HAL_OK)
  {
    Error_Handler();
  }
}

void PeriphCommonClock_Config(void)
{
  RCC_PeriphCLKInitTypeDef PeriphClkInitStruct = {0};

  /** Initializes the peripherals clock
  */
  PeriphClkInitStruct.PeriphClockSelection = RCC_PERIPHCLK_I2C4|RCC_PERIPHCLK_I2C3
                              |RCC_PERIPHCLK_I2C1|RCC_PERIPHCLK_USART1
                              |RCC_PERIPHCLK_UART4|RCC_PERIPHCLK_USART2
                              |RCC_PERIPHCLK_USART3;
  PeriphClkInitStruct.PLL3.PLL3M = 12;
  PeriphClkInitStruct.PLL3.PLL3N = 480;
  PeriphClkInitStruct.PLL3.PLL3P = 2;
  PeriphClkInitStruct.PLL3.PLL3Q = 8;
  PeriphClkInitStruct.PLL3.PLL3R = 8;
  PeriphClkInitStruct.PLL3.PLL3RGE = RCC_PLL3VCIRANGE_1;
  PeriphClkInitStruct.PLL3.PLL3VCOSEL = RCC_PLL3VCOWIDE;
  PeriphClkInitStruct.PLL3.PLL3FRACN = 0;
  PeriphClkInitStruct.Usart234578ClockSelection = RCC_USART234578CLKSOURCE_PLL3;
  PeriphClkInitStruct.Usart16ClockSelection = RCC_USART16CLKSOURCE_PLL3;
  PeriphClkInitStruct.I2c123ClockSelection = RCC_I2C123CLKSOURCE_PLL3;
  PeriphClkInitStruct.I2c4ClockSelection = RCC_I2C4CLKSOURCE_PLL3;
  if (HAL_RCCEx_PeriphCLKConfig(&PeriphClkInitStruct) != HAL_OK)
  {
    Error_Handler();
  }
}

static void MX_I2C1_Init(void)
{

  hi2c1.Instance = I2C1;
  hi2c1.Init.Timing = 0x0050174F;
  hi2c1.Init.OwnAddress1 = 0;
  hi2c1.Init.AddressingMode = I2C_ADDRESSINGMODE_7BIT;
  hi2c1.Init.DualAddressMode = I2C_DUALADDRESS_DISABLE;
  hi2c1.Init.OwnAddress2 = 0;
  hi2c1.Init.OwnAddress2Masks = I2C_OA2_NOMASK;
  hi2c1.Init.GeneralCallMode = I2C_GENERALCALL_DISABLE;
  hi2c1.Init.NoStretchMode = I2C_NOSTRETCH_DISABLE;
  if (HAL_I2C_Init(&hi2c1) != HAL_OK)
  {
    Error_Handler();
  }

  /** Configure Analogue filter
  */
  if (HAL_I2CEx_ConfigAnalogFilter(&hi2c1, I2C_ANALOGFILTER_ENABLE) != HAL_OK)
  {
    Error_Handler();
  }

  /** Configure Digital filter
  */
  if (HAL_I2CEx_ConfigDigitalFilter(&hi2c1, 0) != HAL_OK)
  {
    Error_Handler();
  }

  /** I2C Enable Fast Mode Plus
  */
  HAL_I2CEx_EnableFastModePlus(I2C_FASTMODEPLUS_I2C1);

}

static void MX_I2C3_Init(void)
{

  hi2c3.Instance = I2C3;
  hi2c3.Init.Timing = 0x00B03FDB;
  hi2c3.Init.OwnAddress1 = 208;
  hi2c3.Init.AddressingMode = I2C_ADDRESSINGMODE_7BIT;
  hi2c3.Init.DualAddressMode = I2C_DUALADDRESS_DISABLE;
  hi2c3.Init.OwnAddress2 = 0;
  hi2c3.Init.OwnAddress2Masks = I2C_OA2_NOMASK;
  hi2c3.Init.GeneralCallMode = I2C_GENERALCALL_DISABLE;
  hi2c3.Init.NoStretchMode = I2C_NOSTRETCH_DISABLE;
  if (HAL_I2C_Init(&hi2c3) != HAL_OK)
  {
    Error_Handler();
  }

  /** Configure Analogue filter
  */
  if (HAL_I2CEx_ConfigAnalogFilter(&hi2c3, I2C_ANALOGFILTER_ENABLE) != HAL_OK)
  {
    Error_Handler();
  }

  /** Configure Digital filter
  */
  if (HAL_I2CEx_ConfigDigitalFilter(&hi2c3, 0) != HAL_OK)
  {
    Error_Handler();
  }

}

static void MX_I2C4_Init(void)
{

  hi2c4.Instance = I2C4;
  hi2c4.Init.Timing = 0x00B03FDB;
  hi2c4.Init.OwnAddress1 = 0;
  hi2c4.Init.AddressingMode = I2C_ADDRESSINGMODE_7BIT;
  hi2c4.Init.DualAddressMode = I2C_DUALADDRESS_DISABLE;
  hi2c4.Init.OwnAddress2 = 0;
  hi2c4.Init.OwnAddress2Masks = I2C_OA2_NOMASK;
  hi2c4.Init.GeneralCallMode = I2C_GENERALCALL_DISABLE;
  hi2c4.Init.NoStretchMode = I2C_NOSTRETCH_DISABLE;
  if (HAL_I2C_Init(&hi2c4) != HAL_OK)
  {
    Error_Handler();
  }

  /** Configure Analogue filter
  */
  if (HAL_I2CEx_ConfigAnalogFilter(&hi2c4, I2C_ANALOGFILTER_ENABLE) != HAL_OK)
  {
    Error_Handler();
  }

  /** Configure Digital filter
  */
  if (HAL_I2CEx_ConfigDigitalFilter(&hi2c4, 0) != HAL_OK)
  {
    Error_Handler();
  }

}

static void MX_SPI1_Init(void)
{

  /* SPI1 parameter configuration*/
  hspi1.Instance = SPI1;
  hspi1.Init.Mode = SPI_MODE_MASTER;
  hspi1.Init.Direction = SPI_DIRECTION_2LINES;
  hspi1.Init.DataSize = SPI_DATASIZE_4BIT;
  hspi1.Init.CLKPolarity = SPI_POLARITY_LOW;
  hspi1.Init.CLKPhase = SPI_PHASE_1EDGE;
  hspi1.Init.NSS = SPI_NSS_SOFT;
  hspi1.Init.BaudRatePrescaler = SPI_BAUDRATEPRESCALER_4;
  hspi1.Init.FirstBit = SPI_FIRSTBIT_MSB;
  hspi1.Init.TIMode = SPI_TIMODE_DISABLE;
  hspi1.Init.CRCCalculation = SPI_CRCCALCULATION_DISABLE;
  hspi1.Init.CRCPolynomial = 0x0;
  hspi1.Init.NSSPMode = SPI_NSS_PULSE_ENABLE;
  hspi1.Init.NSSPolarity = SPI_NSS_POLARITY_LOW;
  hspi1.Init.FifoThreshold = SPI_FIFO_THRESHOLD_01DATA;
  hspi1.Init.TxCRCInitializationPattern = SPI_CRC_INITIALIZATION_ALL_ZERO_PATTERN;
  hspi1.Init.RxCRCInitializationPattern = SPI_CRC_INITIALIZATION_ALL_ZERO_PATTERN;
  hspi1.Init.MasterSSIdleness = SPI_MASTER_SS_IDLENESS_00CYCLE;
  hspi1.Init.MasterInterDataIdleness = SPI_MASTER_INTERDATA_IDLENESS_00CYCLE;
  hspi1.Init.MasterReceiverAutoSusp = SPI_MASTER_RX_AUTOSUSP_DISABLE;
  hspi1.Init.MasterKeepIOState = SPI_MASTER_KEEP_IO_STATE_DISABLE;
  hspi1.Init.IOSwap = SPI_IO_SWAP_DISABLE;
  if (HAL_SPI_Init(&hspi1) != HAL_OK)
  {
    Error_Handler();
  }

}

static void MX_TIM1_Init(void)
{

  TIM_ClockConfigTypeDef sClockSourceConfig = {0};
  TIM_MasterConfigTypeDef sMasterConfig = {0};
  TIM_OC_InitTypeDef sConfigOC = {0};
  TIM_BreakDeadTimeConfigTypeDef sBreakDeadTimeConfig = {0};

  htim1.Instance = TIM1;
  htim1.Init.Prescaler = 2;
  htim1.Init.CounterMode = TIM_COUNTERMODE_UP;
  htim1.Init.Period = 4999;
  htim1.Init.ClockDivision = TIM_CLOCKDIVISION_DIV1;
  htim1.Init.RepetitionCounter = 0;
  htim1.Init.AutoReloadPreload = TIM_AUTORELOAD_PRELOAD_DISABLE;
  if (HAL_TIM_Base_Init(&htim1) != HAL_OK)
  {
    Error_Handler();
  }
  sClockSourceConfig.ClockSource = TIM_CLOCKSOURCE_INTERNAL;
  if (HAL_TIM_ConfigClockSource(&htim1, &sClockSourceConfig) != HAL_OK)
  {
    Error_Handler();
  }
  if (HAL_TIM_PWM_Init(&htim1) != HAL_OK)
  {
    Error_Handler();
  }
  sMasterConfig.MasterOutputTrigger = TIM_TRGO_RESET;
  sMasterConfig.MasterOutputTrigger2 = TIM_TRGO2_RESET;
  sMasterConfig.MasterSlaveMode = TIM_MASTERSLAVEMODE_DISABLE;
  if (HAL_TIMEx_MasterConfigSynchronization(&htim1, &sMasterConfig) != HAL_OK)
  {
    Error_Handler();
  }
  sConfigOC.OCMode = TIM_OCMODE_PWM1;
  sConfigOC.Pulse = 0;
  sConfigOC.OCPolarity = TIM_OCPOLARITY_HIGH;
  sConfigOC.OCNPolarity = TIM_OCNPOLARITY_HIGH;
  sConfigOC.OCFastMode = TIM_OCFAST_DISABLE;
  sConfigOC.OCIdleState = TIM_OCIDLESTATE_RESET;
  sConfigOC.OCNIdleState = TIM_OCNIDLESTATE_RESET;
  if (HAL_TIM_PWM_ConfigChannel(&htim1, &sConfigOC, TIM_CHANNEL_1) != HAL_OK)
  {
    Error_Handler();
  }
  if (HAL_TIM_PWM_ConfigChannel(&htim1, &sConfigOC, TIM_CHANNEL_2) != HAL_OK)
  {
    Error_Handler();
  }
  if (HAL_TIM_PWM_ConfigChannel(&htim1, &sConfigOC, TIM_CHANNEL_3) != HAL_OK)
  {
    Error_Handler();
  }
  if (HAL_TIM_PWM_ConfigChannel(&htim1, &sConfigOC, TIM_CHANNEL_4) != HAL_OK)
  {
    Error_Handler();
  }
  sBreakDeadTimeConfig.OffStateRunMode = TIM_OSSR_DISABLE;
  sBreakDeadTimeConfig.OffStateIDLEMode = TIM_OSSI_DISABLE;
  sBreakDeadTimeConfig.LockLevel = TIM_LOCKLEVEL_OFF;
  sBreakDeadTimeConfig.DeadTime = 0;
  sBreakDeadTimeConfig.BreakState = TIM_BREAK_DISABLE;
  sBreakDeadTimeConfig.BreakPolarity = TIM_BREAKPOLARITY_HIGH;
  sBreakDeadTimeConfig.BreakFilter = 0;
  sBreakDeadTimeConfig.Break2State = TIM_BREAK2_DISABLE;
  sBreakDeadTimeConfig.Break2Polarity = TIM_BREAK2POLARITY_HIGH;
  sBreakDeadTimeConfig.Break2Filter = 0;
  sBreakDeadTimeConfig.AutomaticOutput = TIM_AUTOMATICOUTPUT_DISABLE;
  if (HAL_TIMEx_ConfigBreakDeadTime(&htim1, &sBreakDeadTimeConfig) != HAL_OK)
  {
    Error_Handler();
  }
  HAL_TIM_MspPostInit(&htim1);

}

static void MX_TIM2_Init(void)
{

  TIM_ClockConfigTypeDef sClockSourceConfig = {0};
  TIM_MasterConfigTypeDef sMasterConfig = {0};
  TIM_OC_InitTypeDef sConfigOC = {0};

  htim2.Instance = TIM2;
  htim2.Init.Prescaler = 2;
  htim2.Init.CounterMode = TIM_COUNTERMODE_UP;
  htim2.Init.Period = 4999;
  htim2.Init.ClockDivision = TIM_CLOCKDIVISION_DIV1;
  htim2.Init.AutoReloadPreload = TIM_AUTORELOAD_PRELOAD_DISABLE;
  if (HAL_TIM_Base_Init(&htim2) != HAL_OK)
  {
    Error_Handler();
  }
  sClockSourceConfig.ClockSource = TIM_CLOCKSOURCE_INTERNAL;
  if (HAL_TIM_ConfigClockSource(&htim2, &sClockSourceConfig) != HAL_OK)
  {
    Error_Handler();
  }
  if (HAL_TIM_PWM_Init(&htim2) != HAL_OK)
  {
    Error_Handler();
  }
  sMasterConfig.MasterOutputTrigger = TIM_TRGO_RESET;
  sMasterConfig.MasterSlaveMode = TIM_MASTERSLAVEMODE_DISABLE;
  if (HAL_TIMEx_MasterConfigSynchronization(&htim2, &sMasterConfig) != HAL_OK)
  {
    Error_Handler();
  }
  sConfigOC.OCMode = TIM_OCMODE_PWM1;
  sConfigOC.Pulse = 0;
  sConfigOC.OCPolarity = TIM_OCPOLARITY_HIGH;
  sConfigOC.OCFastMode = TIM_OCFAST_DISABLE;
  if (HAL_TIM_PWM_ConfigChannel(&htim2, &sConfigOC, TIM_CHANNEL_1) != HAL_OK)
  {
    Error_Handler();
  }
  if (HAL_TIM_PWM_ConfigChannel(&htim2, &sConfigOC, TIM_CHANNEL_2) != HAL_OK)
  {
    Error_Handler();
  }
  if (HAL_TIM_PWM_ConfigChannel(&htim2, &sConfigOC, TIM_CHANNEL_3) != HAL_OK)
  {
    Error_Handler();
  }
  if (HAL_TIM_PWM_ConfigChannel(&htim2, &sConfigOC, TIM_CHANNEL_4) != HAL_OK)
  {
    Error_Handler();
  }
  HAL_TIM_MspPostInit(&htim2);

}

static void MX_TIM6_Init(void)
{

  TIM_MasterConfigTypeDef sMasterConfig = {0};

  htim6.Instance = TIM6;
  htim6.Init.Prescaler = 239;
  htim6.Init.CounterMode = TIM_COUNTERMODE_UP;
  htim6.Init.Period = 249;
  htim6.Init.AutoReloadPreload = TIM_AUTORELOAD_PRELOAD_DISABLE;
  if (HAL_TIM_Base_Init(&htim6) != HAL_OK)
  {
    Error_Handler();
  }
  sMasterConfig.MasterOutputTrigger = TIM_TRGO_RESET;
  sMasterConfig.MasterSlaveMode = TIM_MASTERSLAVEMODE_DISABLE;
  if (HAL_TIMEx_MasterConfigSynchronization(&htim6, &sMasterConfig) != HAL_OK)
  {
    Error_Handler();
  }

}

static void MX_TIM7_Init(void)
{

  TIM_MasterConfigTypeDef sMasterConfig = {0};

  htim7.Instance = TIM7;
  htim7.Init.Prescaler = 239;
  htim7.Init.CounterMode = TIM_COUNTERMODE_UP;
  htim7.Init.Period = 499;
  htim7.Init.AutoReloadPreload = TIM_AUTORELOAD_PRELOAD_DISABLE;
  if (HAL_TIM_Base_Init(&htim7) != HAL_OK)
  {
    Error_Handler();
  }
  sMasterConfig.MasterOutputTrigger = TIM_TRGO_RESET;
  sMasterConfig.MasterSlaveMode = TIM_MASTERSLAVEMODE_DISABLE;
  if (HAL_TIMEx_MasterConfigSynchronization(&htim7, &sMasterConfig) != HAL_OK)
  {
    Error_Handler();
  }

}

static void MX_TIM13_Init(void)
{

  htim13.Instance = TIM13;
  htim13.Init.Prescaler = 239;
  htim13.Init.CounterMode = TIM_COUNTERMODE_UP;
  htim13.Init.Period = 999;
  htim13.Init.ClockDivision = TIM_CLOCKDIVISION_DIV1;
  htim13.Init.AutoReloadPreload = TIM_AUTORELOAD_PRELOAD_DISABLE;
  if (HAL_TIM_Base_Init(&htim13) != HAL_OK)
  {
    Error_Handler();
  }

}

static void MX_TIM14_Init(void)
{

  htim14.Instance = TIM14;
  htim14.Init.Prescaler = 239;
  htim14.Init.CounterMode = TIM_COUNTERMODE_UP;
  htim14.Init.Period = 124;
  htim14.Init.ClockDivision = TIM_CLOCKDIVISION_DIV1;
  htim14.Init.AutoReloadPreload = TIM_AUTORELOAD_PRELOAD_DISABLE;
  if (HAL_TIM_Base_Init(&htim14) != HAL_OK)
  {
    Error_Handler();
  }

}

static void MX_TIM16_Init(void)
{

  TIM_IC_InitTypeDef sConfigIC = {0};

  htim16.Instance = TIM16;
  htim16.Init.Prescaler = 239;
  htim16.Init.CounterMode = TIM_COUNTERMODE_UP;
  htim16.Init.Period = 65535;
  htim16.Init.ClockDivision = TIM_CLOCKDIVISION_DIV1;
  htim16.Init.RepetitionCounter = 0;
  htim16.Init.AutoReloadPreload = TIM_AUTORELOAD_PRELOAD_DISABLE;
  if (HAL_TIM_Base_Init(&htim16) != HAL_OK)
  {
    Error_Handler();
  }
  if (HAL_TIM_IC_Init(&htim16) != HAL_OK)
  {
    Error_Handler();
  }
  sConfigIC.ICPolarity = TIM_INPUTCHANNELPOLARITY_RISING;
  sConfigIC.ICSelection = TIM_ICSELECTION_DIRECTTI;
  sConfigIC.ICPrescaler = TIM_ICPSC_DIV1;
  sConfigIC.ICFilter = 0;
  if (HAL_TIM_IC_ConfigChannel(&htim16, &sConfigIC, TIM_CHANNEL_1) != HAL_OK)
  {
    Error_Handler();
  }

}

static void MX_UART4_Init(void)
{

  huart4.Instance = UART4;
  huart4.Init.BaudRate = 38400;
  huart4.Init.WordLength = UART_WORDLENGTH_8B;
  huart4.Init.StopBits = UART_STOPBITS_1;
  huart4.Init.Parity = UART_PARITY_NONE;
  huart4.Init.Mode = UART_MODE_TX_RX;
  huart4.Init.HwFlowCtl = UART_HWCONTROL_NONE;
  huart4.Init.OverSampling = UART_OVERSAMPLING_16;
  huart4.Init.OneBitSampling = UART_ONE_BIT_SAMPLE_DISABLE;
  huart4.Init.ClockPrescaler = UART_PRESCALER_DIV1;
  huart4.AdvancedInit.AdvFeatureInit = UART_ADVFEATURE_NO_INIT;
  if (HAL_UART_Init(&huart4) != HAL_OK)
  {
    Error_Handler();
  }
  if (HAL_UARTEx_SetTxFifoThreshold(&huart4, UART_TXFIFO_THRESHOLD_1_8) != HAL_OK)
  {
    Error_Handler();
  }
  if (HAL_UARTEx_SetRxFifoThreshold(&huart4, UART_RXFIFO_THRESHOLD_1_8) != HAL_OK)
  {
    Error_Handler();
  }
  if (HAL_UARTEx_DisableFifoMode(&huart4) != HAL_OK)
  {
    Error_Handler();
  }

}

static void MX_USART1_UART_Init(void)
{

  huart1.Instance = USART1;
  huart1.Init.BaudRate = 38400;
  huart1.Init.WordLength = UART_WORDLENGTH_8B;
  huart1.Init.StopBits = UART_STOPBITS_1;
  huart1.Init.Parity = UART_PARITY_NONE;
  huart1.Init.Mode = UART_MODE_TX_RX;
  huart1.Init.HwFlowCtl = UART_HWCONTROL_NONE;
  huart1.Init.OverSampling = UART_OVERSAMPLING_16;
  huart1.Init.OneBitSampling = UART_ONE_BIT_SAMPLE_DISABLE;
  huart1.Init.ClockPrescaler = UART_PRESCALER_DIV1;
  huart1.AdvancedInit.AdvFeatureInit = UART_ADVFEATURE_NO_INIT;
  if (HAL_UART_Init(&huart1) != HAL_OK)
  {
    Error_Handler();
  }
  if (HAL_UARTEx_SetTxFifoThreshold(&huart1, UART_TXFIFO_THRESHOLD_1_8) != HAL_OK)
  {
    Error_Handler();
  }
  if (HAL_UARTEx_SetRxFifoThreshold(&huart1, UART_RXFIFO_THRESHOLD_1_8) != HAL_OK)
  {
    Error_Handler();
  }
  if (HAL_UARTEx_DisableFifoMode(&huart1) != HAL_OK)
  {
    Error_Handler();
  }

}

static void MX_USART2_UART_Init(void)
{

  huart2.Instance = USART2;
  huart2.Init.BaudRate = 38400;
  huart2.Init.WordLength = UART_WORDLENGTH_8B;
  huart2.Init.StopBits = UART_STOPBITS_1;
  huart2.Init.Parity = UART_PARITY_NONE;
  huart2.Init.Mode = UART_MODE_TX_RX;
  huart2.Init.HwFlowCtl = UART_HWCONTROL_NONE;
  huart2.Init.OverSampling = UART_OVERSAMPLING_16;
  huart2.Init.OneBitSampling = UART_ONE_BIT_SAMPLE_DISABLE;
  huart2.Init.ClockPrescaler = UART_PRESCALER_DIV1;
  huart2.AdvancedInit.AdvFeatureInit = UART_ADVFEATURE_NO_INIT;
  if (HAL_UART_Init(&huart2) != HAL_OK)
  {
    Error_Handler();
  }
  if (HAL_UARTEx_SetTxFifoThreshold(&huart2, UART_TXFIFO_THRESHOLD_1_8) != HAL_OK)
  {
    Error_Handler();
  }
  if (HAL_UARTEx_SetRxFifoThreshold(&huart2, UART_RXFIFO_THRESHOLD_1_8) != HAL_OK)
  {
    Error_Handler();
  }
  if (HAL_UARTEx_DisableFifoMode(&huart2) != HAL_OK)
  {
    Error_Handler();
  }

}

static void MX_USART3_UART_Init(void)
{

  huart3.Instance = USART3;
  huart3.Init.BaudRate = 38400;
  huart3.Init.WordLength = UART_WORDLENGTH_8B;
  huart3.Init.StopBits = UART_STOPBITS_1;
  huart3.Init.Parity = UART_PARITY_NONE;
  huart3.Init.Mode = UART_MODE_TX_RX;
  huart3.Init.HwFlowCtl = UART_HWCONTROL_NONE;
  huart3.Init.OverSampling = UART_OVERSAMPLING_16;
  huart3.Init.OneBitSampling = UART_ONE_BIT_SAMPLE_DISABLE;
  huart3.Init.ClockPrescaler = UART_PRESCALER_DIV1;
  huart3.AdvancedInit.AdvFeatureInit = UART_ADVFEATURE_NO_INIT;
  if (HAL_UART_Init(&huart3) != HAL_OK)
  {
    Error_Handler();
  }
  if (HAL_UARTEx_SetTxFifoThreshold(&huart3, UART_TXFIFO_THRESHOLD_1_8) != HAL_OK)
  {
    Error_Handler();
  }
  if (HAL_UARTEx_SetRxFifoThreshold(&huart3, UART_RXFIFO_THRESHOLD_1_8) != HAL_OK)
  {
    Error_Handler();
  }
  if (HAL_UARTEx_DisableFifoMode(&huart3) != HAL_OK)
  {
    Error_Handler();
  }

}

static void MX_BDMA_Init(void)
{

  /* DMA controller clock enable */
  __HAL_RCC_BDMA_CLK_ENABLE();

  /* DMA interrupt init */
  /* BDMA_Channel0_IRQn interrupt configuration */
  HAL_NVIC_SetPriority(BDMA_Channel0_IRQn, 0, 0);
  HAL_NVIC_EnableIRQ(BDMA_Channel0_IRQn);
  /* BDMA_Channel1_IRQn interrupt configuration */
  HAL_NVIC_SetPriority(BDMA_Channel1_IRQn, 0, 0);
  HAL_NVIC_EnableIRQ(BDMA_Channel1_IRQn);

}

static void MX_DMA_Init(void)
{

  /* DMA controller clock enable */
  __HAL_RCC_DMA1_CLK_ENABLE();
  __HAL_RCC_DMA2_CLK_ENABLE();

  /* DMA interrupt init */
  /* DMA1_Stream0_IRQn interrupt configuration */
  HAL_NVIC_SetPriority(DMA1_Stream0_IRQn, 0, 0);
  HAL_NVIC_EnableIRQ(DMA1_Stream0_IRQn);
  /* DMA1_Stream1_IRQn interrupt configuration */
  HAL_NVIC_SetPriority(DMA1_Stream1_IRQn, 0, 0);
  HAL_NVIC_EnableIRQ(DMA1_Stream1_IRQn);
  /* DMA1_Stream2_IRQn interrupt configuration */
  HAL_NVIC_SetPriority(DMA1_Stream2_IRQn, 0, 0);
  HAL_NVIC_EnableIRQ(DMA1_Stream2_IRQn);
  /* DMA1_Stream3_IRQn interrupt configuration */
  HAL_NVIC_SetPriority(DMA1_Stream3_IRQn, 0, 0);
  HAL_NVIC_EnableIRQ(DMA1_Stream3_IRQn);
  /* DMA1_Stream4_IRQn interrupt configuration */
  HAL_NVIC_SetPriority(DMA1_Stream4_IRQn, 0, 0);
  HAL_NVIC_EnableIRQ(DMA1_Stream4_IRQn);
  /* DMA1_Stream5_IRQn interrupt configuration */
  HAL_NVIC_SetPriority(DMA1_Stream5_IRQn, 0, 0);
  HAL_NVIC_EnableIRQ(DMA1_Stream5_IRQn);
  /* DMA1_Stream6_IRQn interrupt configuration */
  HAL_NVIC_SetPriority(DMA1_Stream6_IRQn, 0, 0);
  HAL_NVIC_EnableIRQ(DMA1_Stream6_IRQn);
  /* DMA1_Stream7_IRQn interrupt configuration */
  HAL_NVIC_SetPriority(DMA1_Stream7_IRQn, 0, 0);
  HAL_NVIC_EnableIRQ(DMA1_Stream7_IRQn);
  /* DMA2_Stream0_IRQn interrupt configuration */
  HAL_NVIC_SetPriority(DMA2_Stream0_IRQn, 0, 0);
  HAL_NVIC_EnableIRQ(DMA2_Stream0_IRQn);
  /* DMA2_Stream1_IRQn interrupt configuration */
  HAL_NVIC_SetPriority(DMA2_Stream1_IRQn, 0, 0);
  HAL_NVIC_EnableIRQ(DMA2_Stream1_IRQn);
  /* DMA2_Stream2_IRQn interrupt configuration */
  HAL_NVIC_SetPriority(DMA2_Stream2_IRQn, 0, 0);
  HAL_NVIC_EnableIRQ(DMA2_Stream2_IRQn);
  /* DMA2_Stream3_IRQn interrupt configuration */
  HAL_NVIC_SetPriority(DMA2_Stream3_IRQn, 0, 0);
  HAL_NVIC_EnableIRQ(DMA2_Stream3_IRQn);
  /* DMA2_Stream4_IRQn interrupt configuration */
  HAL_NVIC_SetPriority(DMA2_Stream4_IRQn, 0, 0);
  HAL_NVIC_EnableIRQ(DMA2_Stream4_IRQn);
  /* DMA2_Stream5_IRQn interrupt configuration */
  HAL_NVIC_SetPriority(DMA2_Stream5_IRQn, 0, 0);
  HAL_NVIC_EnableIRQ(DMA2_Stream5_IRQn);
  /* DMA2_Stream6_IRQn interrupt configuration */
  HAL_NVIC_SetPriority(DMA2_Stream6_IRQn, 0, 0);
  HAL_NVIC_EnableIRQ(DMA2_Stream6_IRQn);
  /* DMA2_Stream7_IRQn interrupt configuration */
  HAL_NVIC_SetPriority(DMA2_Stream7_IRQn, 0, 0);
  HAL_NVIC_EnableIRQ(DMA2_Stream7_IRQn);

}

static void MX_GPIO_Init(void)
{
  GPIO_InitTypeDef GPIO_InitStruct = {0};

  /* GPIO Ports Clock Enable */
  __HAL_RCC_GPIOE_CLK_ENABLE();
  __HAL_RCC_GPIOH_CLK_ENABLE();
  __HAL_RCC_GPIOC_CLK_ENABLE();
  __HAL_RCC_GPIOA_CLK_ENABLE();
  __HAL_RCC_GPIOB_CLK_ENABLE();
  __HAL_RCC_GPIOD_CLK_ENABLE();

  /*Configure GPIO pin Output Level */
  HAL_GPIO_WritePin(GPIOE, GPIO_PIN_4, GPIO_PIN_RESET);

  /*Configure GPIO pin Output Level */
  HAL_GPIO_WritePin(GPIOC, GPIO_PIN_0|GPIO_PIN_1|GPIO_PIN_2|GPIO_PIN_3
                          |GPIO_PIN_5, GPIO_PIN_RESET);

  /*Configure GPIO pin Output Level */
  HAL_GPIO_WritePin(GPIOD, GPIO_PIN_11, GPIO_PIN_RESET);

  /*Configure GPIO pin : PE3 */
  GPIO_InitStruct.Pin = GPIO_PIN_3;
  GPIO_InitStruct.Mode = GPIO_MODE_INPUT;
  GPIO_InitStruct.Pull = GPIO_NOPULL;
  HAL_GPIO_Init(GPIOE, &GPIO_InitStruct);

  /*Configure GPIO pin : PE4 */
  GPIO_InitStruct.Pin = GPIO_PIN_4;
  GPIO_InitStruct.Mode = GPIO_MODE_OUTPUT_PP;
  GPIO_InitStruct.Pull = GPIO_NOPULL;
  GPIO_InitStruct.Speed = GPIO_SPEED_FREQ_LOW;
  HAL_GPIO_Init(GPIOE, &GPIO_InitStruct);

  /*Configure GPIO pins : PE5 PE6 */
  GPIO_InitStruct.Pin = GPIO_PIN_5|GPIO_PIN_6;
  GPIO_InitStruct.Mode = GPIO_MODE_AF_PP;
  GPIO_InitStruct.Pull = GPIO_NOPULL;
  GPIO_InitStruct.Speed = GPIO_SPEED_FREQ_LOW;
  GPIO_InitStruct.Alternate = GPIO_AF4_TIM15;
  HAL_GPIO_Init(GPIOE, &GPIO_InitStruct);

  /*Configure GPIO pins : PC0 PC1 PC2 PC3
                           PC5 */
  GPIO_InitStruct.Pin = GPIO_PIN_0|GPIO_PIN_1|GPIO_PIN_2|GPIO_PIN_3
                          |GPIO_PIN_5;
  GPIO_InitStruct.Mode = GPIO_MODE_OUTPUT_PP;
  GPIO_InitStruct.Pull = GPIO_NOPULL;
  GPIO_InitStruct.Speed = GPIO_SPEED_FREQ_LOW;
  HAL_GPIO_Init(GPIOC, &GPIO_InitStruct);

  /*Configure GPIO pin : PD11 */
  GPIO_InitStruct.Pin = GPIO_PIN_11;
  GPIO_InitStruct.Mode = GPIO_MODE_OUTPUT_PP;
  GPIO_InitStruct.Pull = GPIO_NOPULL;
  GPIO_InitStruct.Speed = GPIO_SPEED_FREQ_LOW;
  HAL_GPIO_Init(GPIOD, &GPIO_InitStruct);

  /*AnalogSwitch Config */
  HAL_SYSCFG_AnalogSwitchConfig(SYSCFG_SWITCH_PC2, SYSCFG_SWITCH_PC2_CLOSE);

  /*AnalogSwitch Config */
  HAL_SYSCFG_AnalogSwitchConfig(SYSCFG_SWITCH_PC3, SYSCFG_SWITCH_PC3_CLOSE);

}

void Error_Handler(void)
{
  __disable_irq();
  while (1)
  {
  }
}
